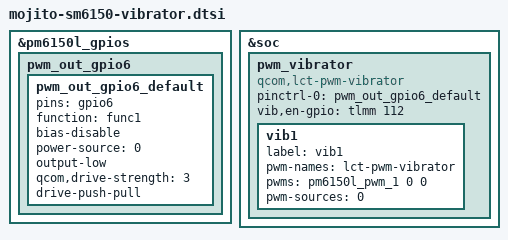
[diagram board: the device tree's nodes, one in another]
/*
 * Copyright (c) 2019, The Linux Foundation. All rights reserved.
 * Copyright (C) 2021 XiaoMi, Inc.
 *
 * This program is free software; you can redistribute it and/or modify
 * it under the terms of the GNU General Public License version 2 and
 * only version 2 as published by the Free Software Foundation.
 *
 * This program is distributed in the hope that it will be useful,
 * but WITHOUT ANY WARRANTY; without even the implied warranty of
 * MERCHANTABILITY or FITNESS FOR A PARTICULAR PURPOSE.  See the
 * GNU General Public License for more details.
 */

&pm6150l_gpios {
	pwm_out_gpio6 {
		pwm_out_gpio6_default: pwm_out_gpio6_default {
			pins = "gpio6";
			function = "func1";
			bias-disable;
			power-source = <0>;
			output-low;
			qcom,drive-strength = <3>;
			drive-push-pull;
		};
	};
};

&soc {
	pwm_vibrator {
		status = "ok";
		compatible = "qcom,lct-pwm-vibrator";
		pinctrl-names = "default";
		pinctrl-0 = <&pwm_out_gpio6_default>;
		vib,en-gpio = <&tlmm 112 0>;
		vib1 {
			label = "vib1";
			pwm-names = "lct-pwm-vibrator";
			pwms = <&pm6150l_pwm_1 0 0>;
			pwm-sources = <0>;
		};
	};
};
